VERSION "1.0"

NS_ :

BS_:

BU_: EngineECU ABSECU TransECU

VERSION "1.0"

NS_ :

BS_:

BU_: EngineECU ABSECU

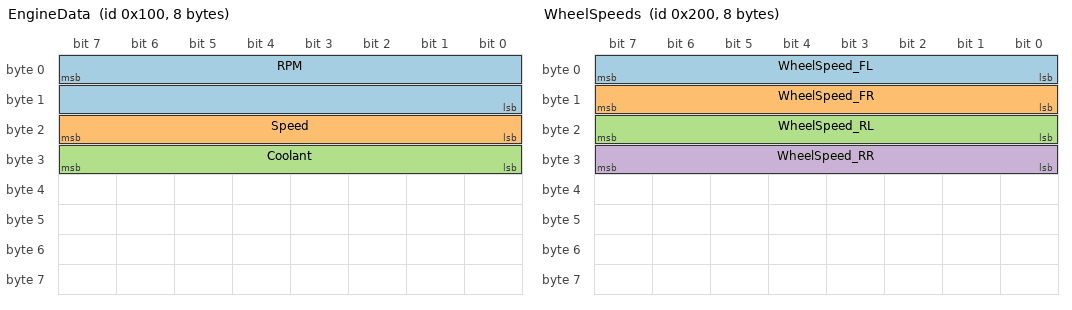
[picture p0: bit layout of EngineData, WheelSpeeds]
BO_ 256 EngineData: 8 EngineECU
 SG_ RPM : 7|16@0+ (4,0) [0|16383] "rpm" EngineECU
 SG_ Speed : 16|8@1+ (1,0) [0|255] "kmh" EngineECU
 SG_ Coolant : 24|8@1+ (1,-40) [-40|215] "C" EngineECU

BO_ 512 WheelSpeeds: 8 ABSECU
 SG_ WheelSpeed_FL : 0|8@1+ (1,0) [0|255] "kmh" ABSECU
 SG_ WheelSpeed_FR : 8|8@1+ (1,0) [0|255] "kmh" ABSECU
 SG_ WheelSpeed_RL : 16|8@1+ (1,0) [0|255] "kmh" ABSECU
 SG_ WheelSpeed_RR : 24|8@1+ (1,0) [0|255] "kmh" ABSECU

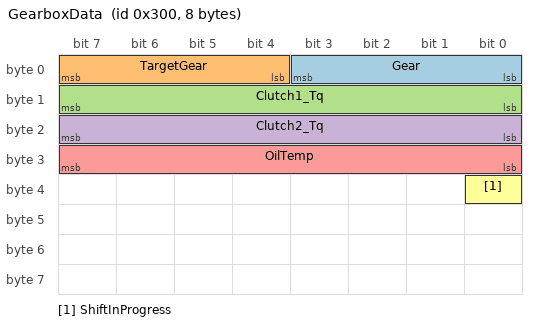
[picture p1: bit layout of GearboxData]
BO_ 768 GearboxData: 8 TransECU
 SG_ Gear : 0|4@1+ (1,0) [0|15] "gear" TransECU
 SG_ TargetGear : 4|4@1+ (1,0) [0|15] "gear" TransECU
 SG_ Clutch1_Tq : 8|8@1+ (1,0) [0|255] "%" TransECU
 SG_ Clutch2_Tq : 16|8@1+ (1,0) [0|255] "%" TransECU
 SG_ OilTemp : 24|8@1+ (1,-40) [-40|215] "C" TransECU
 SG_ ShiftInProgress : 32|1@1+ (1,0) [0|1] "" TransECU
